# M55M1 register map
File version: 1.0
Registers are 32-bit, read-write, reset 0x0 unless marked. A register's access mark holds for its fields unless they carry their own. Offsets are from the block's base; [hi:lo] are bit positions; {n}, {i} and the like mark numbered series; 'fields as' and 'values as' point back to an identical list.

## LPADC0 — LPADC Register Map
Base 0x40442000
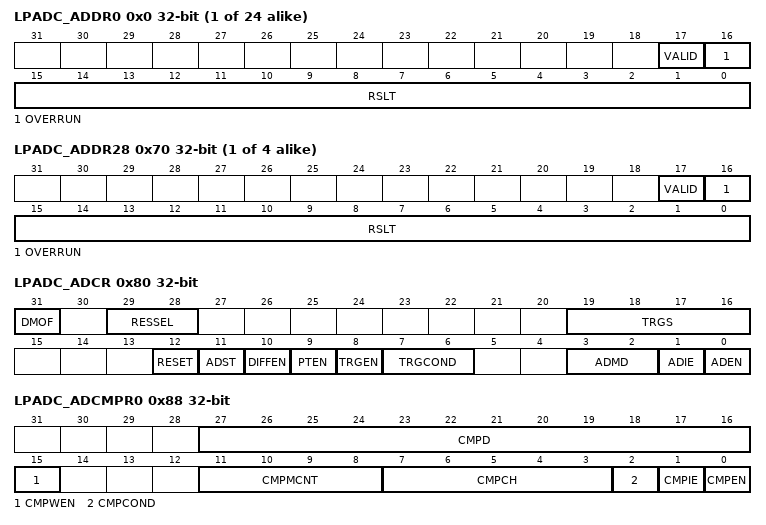
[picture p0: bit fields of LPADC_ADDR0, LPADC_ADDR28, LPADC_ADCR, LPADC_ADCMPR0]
{0x0+4i} LPADC_ADDR{i} ro (i=0..23) — ADC Data Register {i}
  [17] VALID — Valid Flag (Read Only). This bit will be set to 1 when the conversion of the corresponding channel is completed. This bit will be cleared to 0 by hardware after ADDR register is read.
    0=Data in RSLT bits is not valid; 1=Data in RSLT bits is valid
  [16] OVERRUN — Overrun Flag (Read Only). If converted data in RSLT bits has not been read before new conversion result is loaded to this register, OVERRUN bit is set to 1. It is cleared by hardware after ADDR register is read.
    0=Data in RSLT bits is not overwritten; 1=Data in RSLT bits is overwritten
  [15:0] RSLT — A/D Conversion Result (Read Only). This field contains conversion result of ADC.
{0x0+4i} LPADC_ADDR{i} ro (i=28..31) — ADC Data Register {i}
  fields as LPADC_ADDR0
0x80 LPADC_ADCR — ADC Control Register
  [31] DMOF — Differential Input Mode Output Format. If user enables differential input mode, the conversion result can be expressed with binary straight format (unsigned format) or 2's complement format (signed format).
    0=A/D Conversion result will be filled in RSLT at ADDRx registers with unsigned format (straight binary format); 1=A/D Conversion result will be filled in RSLT at ADDRx registers with 2's complement format
  [29:28] RESSEL — Resolution Select Bits
    0=ADC resolution 12 bits; 1=ADC resolution 10 bits; 2=ADC resolution 8 bits
  [19:16] TRGS — Hardware Trigger Source. Note: Software should clear TRGEN bit and ADST(LPADC_ADCR[11]) bit to 0 before changing TRGS bits.
    0=A/D conversion is started by external LPADC0_ST pin; 2=A/D conversion is started by BPWM trigger; 4=A/D conversion is started by EPWM trigger; {v}=ACMP{v-8} interrupt event (v=8..11)
  [12] RESET — ADC RESET (Write Protect). If user writes this bit, the ADC analog macro will reset. Calibration data in macro will be deleted, but registers in ADC controller will keep. Note: This bit is cleared by hardware.
  [11] ADST — A/D Conversion Start or Calibration Start. ADST bit can be set to 1 from below sources: software, external pin LPADC0_ST, BPWM trigger, EPWM trigger and ACMP interrupt event. ADST bit will be cleared to 0 by hardware automatically at the ends of Single mode, Single-cycle Scan mode and Calibration mode. In Continuous Scan mode and Burst mode, A/D conversion is continuously performed until software writes 0 to this bit or chip is reset.
    0=Conversion stops and A/D converter enters idle state; 1=Conversion starts or Calibration Start
  [10] DIFFEN — Differential Input Mode Control. Note: In Differential Input mode, only the even number of the two corresponding channels needs to be enabled in ADCHER register. The conversion result will be placed to the corresponding data register of the enabled channel.
    0=Single-end analog input mode; 1=Differential analog input mode
  [9] PTEN — LPPDMA Transfer Enable Bit. When A/D conversion is completed, the converted data is loaded into ADDR0~23 and ADDR28~ADDR31. Software can enable this bit to generate a LPPDMA data transfer request.
    0=LPPDMA data transfer Disabled; 1=LPPDMA data transfer in ADDR 0~23 and ADDR28~ADDR31 Enabled
  [8] TRGEN — External Trigger Enable Bit. Enable or disable triggering of A/D conversion by external LPADC0_ST pin, EPWM trigger, BPWM trigger and ACMP interrupt event. If external trigger is enabled, the ADST(LPADC_ADCR[11]) bit can be set to 1 by the selected hardware trigger source. Note: The ADC external trigger function is only supported in Single-cycle Scan mode.
    0=External trigger Disabled; 1=External trigger Enabled
  [7:6] TRGCOND — External Trigger Condition. These two bits decide external pin LPADC0_ST trigger event is level or edge. The signal must be kept at stable state at least 8 PCLKs for level trigger and at least 4 PCLKs for edge trigger.
    0=Low level; 1=High level; 2=Falling edge; 3=Rising edge
  [3:2] ADMD — A/D Converter Operation Mode Control. Note 1: When changing the operation mode, software should clear ADST(LPADC_ADCR[11]) bit first. Note 2: In Burst mode, the A/D result data is always at ADC Data Register 0.
    0=Single conversion; 1=Burst conversion; 2=Single-cycle Scan; 3=Continuous Scan
  [1] ADIE — A/D Interrupt Enable Bit. A/D conversion end interrupt request is generated if ADIE bit is set to 1.
    0=A/D interrupt function Disabled; 1=A/D interrupt function Enabled
  [0] ADEN — A/D Converter Enable Bit. Note: Before starting A/D conversion function, this bit should be set to 1. Clear it to 0 to disable A/D converter analog circuit to save power consumption.
    0=A/D converter Disabled; 1=A/D converter Enabled
0x84 LPADC_ADCHER — ADC Channel Enable Register
  [31:0] CHEN — Analog Input Channel Enable Control. Set CHEN [23:0] bits to enable the corresponding analog external input channel 23 ~ 0. If DIFFEN bit is set to 1, only the even number channel needs to be enabled. Besides, setting the CHEN [28] bit will enable internal channel for temperature sensor output voltage , setting the CHEN [29] bit will enable internal channel for AVDD divided by four, setting the CHEN [30] bit will enable internal channel for VBAT divided by four , setting the CHEN [31] bit will enable internal channel for band-gap voltage . Other bits are reserved. Note 1: If the internal channel for AVDD divide by four (CHEN[28]), band-gap voltage (CHEN[29]), temperature sensor output voltage (CHEN[30]) or VBAT divided by four (CHEN[31]) is active, the maximum sampling rate will be 300k SPS. Note 2: The frequency of writing CHEN must be less than LPADC0CLK/3.
    0=Channel Disabled; 1=Channel Enabled
0x88 LPADC_ADCMPR0 — ADC Compare Register 0
  [27:16] CMPD — Comparison Data. The 12-bit data is used to compare with conversion result of specified channel. Note: CMPD bits should be filled in unsigned format (straight binary format).
  [15] CMPWEN — Compare Window Mode Enable Bit. Note: This bit is only presented in ADCMPR0 register.
    0=Compare Window Mode Disabled; 1=Compare Window Mode Enabled
  [11:8] CMPMCNT — Compare Match Count. When the specified A/D channel analog conversion result matches the compare condition defined by CMPCOND (LPADC_ADCMPRx[2]), the internal match counter will increase 1. When the internal counter reaches the value to (CMPMCNT +1), the CMPFx(LPADC_ADSR0[1]/[2]) bit will be set.
  [7:3] CMPCH — Compare Channel Selection
    {v}=Channel {v} conversion result is selected to be compared (v=0..23); 28=Temperature sensor voltage conversion result is selected to be compared; 29=AVDD/4 channel conversion result is selected to be compared; 30=VBAT/4 conversion result is selected to be compared; 31=Band-gap voltage channel conversion result is selected to be compared
  [2] CMPCOND — Compare Condition. Note: When the internal counter reaches to (CMPMCNT +1), the CMPFx(LPADC_ADSR0[1]/[2]) bit will be set.
    0=Set the compare condition as that when a 12-bit A/D conversion result is less than the 12-bit CMPD (ADCMPRx[27:16]), the internal match counter will increase one; 1=Set the compare condition as that when a 12-bit A/D conversion result is greater than or equal to the 12-bit CMPD (ADCMPRx[27:16]), the internal match counter will increase one
  [1] CMPIE — Compare Interrupt Enable Bit. If the compare function is enabled and the compare condition matches the setting of CMPCOND (ADCMPRx[2]) and CMPMCNT (ADCMPRx[11:8]), CMPFx(LPADC_ADSR0[1]/[2]) bit will be asserted, in the meanwhile, if CMPIE bit is set to 1, a compare interrupt request is generated.
    0=Compare function interrupt Disabled; 1=Compare function interrupt Enabled
  [0] CMPEN — Compare Enable Bit. Set this bit to 1 to enable ADC controller to compare CMPD (ADCMPRx[27:16]) with specified channel conversion result when converted data is loaded into ADDR register.
    0=Compare function Disabled; 1=Compare function Enabled
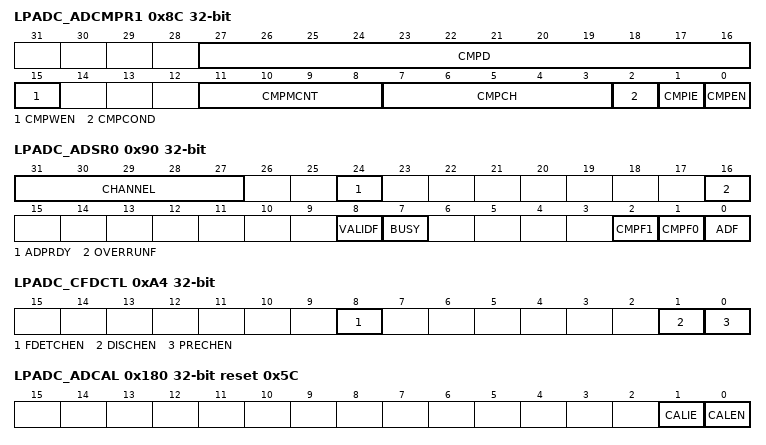
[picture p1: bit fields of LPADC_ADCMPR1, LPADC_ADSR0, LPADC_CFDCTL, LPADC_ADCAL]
0x8C LPADC_ADCMPR1 — ADC Compare Register 1
  fields as LPADC_ADCMPR0
0x90 LPADC_ADSR0 — ADC Status Register0
  [31:27] CHANNEL ro — Current Conversion Channel (Read Only)
  [24] ADPRDY ro — ADC Power On Ready (Read Only). After set ADEN (LPADC_ADCR[0]) to 1, the ADPRDY will set to 1 after ADC block power on ready. Note: The LPADC can start converting after ADPRDY is 1.
  [16] OVERRUNF ro — Overrun Flag (Read Only). If any one of OVERRUN (ADDRx[16]) is set, this flag will be set to 1. Note: When ADC is in burst mode and the FIFO is overrun, this flag will be set to 1.
  [8] VALIDF ro — Data Valid Flag (Read Only). If any one of VALID (ADDRx[17]) is set, this flag will be set to 1. Note: When ADC is in burst mode and any conversion result is valid, this flag will be set to 1.
  [7] BUSY ro — BUSY/IDLE (Read Only). This bit is a mirror of ADST(LPADC_ADCR[11]) bit in ADCR register.
    0=A/D converter is in idle state; 1=A/D converter is busy at conversion
  [2] CMPF1 — Compare Flag 1. When the A/D conversion result of the selected channel meets setting condition in ADCMPR1 register, this bit is set to 1; it is cleared by writing 1 to it
    0=Conversion result in ADDR does not meet ADCMPR1 setting; 1=Conversion result in ADDR meets ADCMPR1 setting
  [1] CMPF0 — Compare Flag 0. When the A/D conversion result of the selected channel meets setting condition in ADCMPR0 register then this bit is set to 1. This bit is cleared by writing 1 to it.
    0=Conversion result in ADDR does not meet ADCMPR0 setting; 1=Conversion result in ADDR meets ADCMPR0 setting
  [0] ADF — A/D Conversion End Flag. A status flag that indicates the end of A/D conversion. Software can write 1 to clear this bit. The ADF bit is set to 1 at the following three conditions: When A/D conversion ends in Single mode. When A/D conversion ends on all specified channels in Single-cycle Scan mode and Continuous Scan mode. When more than or equal to 8 samples in FIFO in Burst mode.
0x94 LPADC_ADSR1 ro — ADC Status Register1
  [31:0] VALID — Data Valid Flag (Read Only). VALID[31, 30, 29, 28, 23:0] are the mirror of the VALID bits in ADDR31[17], ADDR30[17], ADDR29[17], ADDR28[17], ADDR23[17]~ ADDR0[17]. The other bits are reserved. Note: When ADC is in burst mode and any conversion result is valid, VALID[31, 30, 29, 28, 23:0] will be set to 1.
0x98 LPADC_ADSR2 ro — ADC Status Register2
  [31:0] OVERRUN — Overrun Flag (Read Only). OVERRUN[31, 30, 29, 28, 23:0] are the mirror of the OVERRUN bit in ADDR31[16], ADDR30[16], ADDR29[16], ADDR28[16], ADDR23[16] ~ ADDR0[16]. The other bits are reserved. Note: When ADC is in burst mode and the FIFO is overrun, OVERRUN[31, 30, 29, 28, 23:0] will be set to 1.
0xA0 LPADC_ESMPCTL — ADC Extend Sample Time Control Register
  [13:0] EXTSMPT — ADC Sampling Time Extend. When ADC converting at high conversion rate, the sampling time of analog input voltage may not enough if input channel loading is heavy, user can extend ADC sampling time after trigger source is coming to get enough sampling time. The range of start delay time is from 0~16383 ADC clock.
0xA4 LPADC_CFDCTL — ADC Channel Floating Detect Control Register
  [8] FDETCHEN — Floating Detect Channel Enable Bit
    0=Floating Detect Channel Disabled; 1=Floating Detect Channel Enabled
  [1] DISCHEN — Discharge Enable Bit. Note: Analog input voltage is 1/2 VREF when PRECHEN and DISCHEN are all enable.
    0=Channel discharge Disabled; 1=Channel discharge Enabled
  [0] PRECHEN — Precharge Enable Bit. Note: Analog input voltage is 1/2 VREF when PRECHEN and DISCHEN are all enable.
    0=Channel precharge Disabled; 1=Channel precharge Enabled
0x100 LPADC_ADPDMA ro — ADC LPPDMA Current Transfer Data Register
  [17:0] CURDAT — ADC LPPDMA Current Transfer Data Register (Read Only). When LPPDMA transferring, read this register can monitor current LPPDMA transfer data. Current LPPDMA transfer data could be the content of ADDR0 ~ ADDR23, ADDR28, ADDR29, ADDR30 and ADDR31 registers.
0x180 LPADC_ADCAL reset 0x5C — ADC Calibration Mode Register
  [1] CALIE — Calibration Interrupt Enable Bit. If calibration function is enabled and the calibration is finished, CALIF bit will be asserted, in the meanwhile, if CALIE bit is set to 1, a calibration interrupt request is generated.
    0=Calibration function Interrupt Disabled; 1=Calibration function Interrupt Enabled
  [0] CALEN — Calibration Function Enable Bit. Note: If chip is powered off, calibration function should be executed again.
    0=Calibration function Disabled
0x184 LPADC_ADCALSTS — ADC Calibration Status Register
  [0] CALIF — Calibration Finish Interrupt Flag. If calibration is finished, this flag will be set to 1. It is cleared by writing 1 to it.
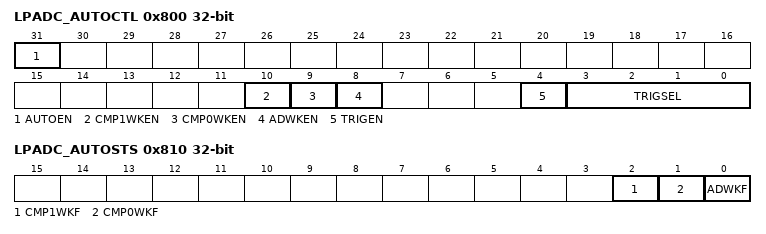
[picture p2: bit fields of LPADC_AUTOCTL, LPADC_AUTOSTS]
0x800 LPADC_AUTOCTL — ADC Auto Operation Control Register
  [31] AUTOEN — Automatic Operation Mode Enable Bit
    0=LPADC automatic operation Disabled; 1=LPADC automatic operation Enabled
  [10] CMP1WKEN — Automatic Operation Mode Comparator 1 Wake-up Enable Bit
    0=LPADC automatic operation comparator 1 wake-up Disabled; 1=LPADC automatic operation comparator 1 wake-up Enabled
  [9] CMP0WKEN — Automatic Operation Mode Comparator 0 Wake-up Enable Bit
    0=LPADC automatic operation comparator 0 wake-up Disabled; 1=LPADC automatic operation comparator 0 wake-up Enabled
  [8] ADWKEN — Automatic Operation Mode Conversion End Wake-up Enable Bit
    0=LPADC automatic operation conversion end wake-up Disabled; 1=LPADC automatic operation conversion end wake-up Enabled
  [4] TRIGEN — Automatic Operation Trigger Enable Bit. When automatic operation mode is enabled, the LPADC will start working if LPADC is triggered by a event sent from the trigger source selected by TRIGSEL[3:0] after this bit is set to 1.
    0=LPADC Automatic Operation Trigger disabled; 1=LPADC Automatic Operation Trigger enabled
  [3:0] TRIGSEL — Automatic Operation Trigger Source Select
    0=Auto-operation Trigger Source from LPTMR0; 1=Auto-operation Trigger Source from LPTMR1; 2=Auto-operation Trigger Source from TTMR0; 3=Auto-operation Trigger Source from TTMR1; 4=Auto-operation Trigger Source from WKIOA0; 5=Auto-operation Trigger Source from WKIOB0; 6=Auto-operation Trigger Source from WKIOC0; 7=Auto-operation Trigger Source from WKIOD0; {v}=Auto-operation Trigger Source from ACMP{v-8} (v=8..11)
0x804 LPADC_AUTOSTRG wo — ADC Auto Operation Software Trigger Register
  [0] SWTRIG — Automatic Operation Software Trigger Bit. Write 1 to this bit will trigger LPADC start automatic operation. Note: This bit will be auto cleared by hardware
0x810 LPADC_AUTOSTS — ADC Auto Operation Status Register
  [2] CMP1WKF — Automatic Operation Compare 1 Wake-up Flag Bit. When automatic operation mode is enabled, and the conversion result monitor comparator 1 is match setting criteria, this flag will be set. If CMP1WKEN also set to 1, the chip will be wake-up. Software can write one to clear this bit
  [1] CMP0WKF — Automatic Operation Compare 0 Wake-up Flag Bit. When automatic operation mode is enabled, and the conversion result monitor comparator 0 is match setting criteria, this flag will be set. If CMP0WKEN also set to 1, the chip will be wake-up. Software can write one to clear this bit
  [0] ADWKF — Automatic Operation Conversion End Wake-up Flag Bit. When automatic operation mode is enabled, and the conversion is finished, this flag will be set. If WKEN also set to 1, the chip will be wake-up. Software can write one to clear this bit

## LPADC0_NS — LPADC Register Map
Base 0x50442000
Registers as LPADC0; these are added or differ:
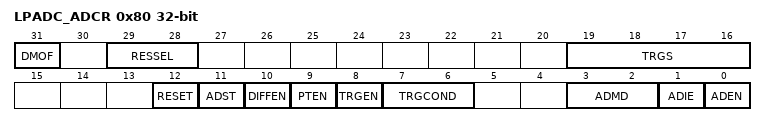
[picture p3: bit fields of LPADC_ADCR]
0x80 LPADC_ADCR — ADC Control Register
  fields as LPADC0.LPADC_ADCR
0x84 LPADC_ADCHER — ADC Channel Enable Register
  fields as LPADC0.LPADC_ADCHER
